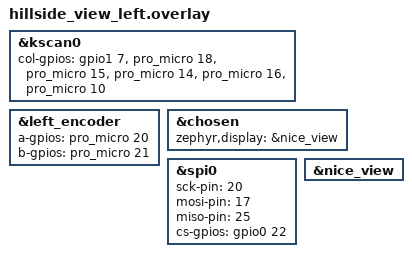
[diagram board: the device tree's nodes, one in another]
/*
 * Copyright (c) 2022 The ZMK Contributors
 *
 * SPDX-License-Identifier: MIT
 */

#include "hillside_view.dtsi"

&kscan0  {
	col-gpios
		= <&gpio1 7 GPIO_ACTIVE_HIGH>
		, <&pro_micro 18 GPIO_ACTIVE_HIGH>
		, <&pro_micro 15 GPIO_ACTIVE_HIGH>
		, <&pro_micro 14 GPIO_ACTIVE_HIGH>
		, <&pro_micro 16 GPIO_ACTIVE_HIGH>
		, <&pro_micro 10 GPIO_ACTIVE_HIGH>
		;
};

&left_encoder {
	status = "okay";
  a-gpios = <&pro_micro 20 (GPIO_ACTIVE_HIGH | GPIO_PULL_UP)>;
  b-gpios = <&pro_micro 21 (GPIO_ACTIVE_HIGH | GPIO_PULL_UP)>;
};

&chosen {
  zephyr,display = &nice_view;
};

// nice view bus
&spi0 {
  status = "okay";
  sck-pin = <20>;
  mosi-pin = <17>;
  miso-pin = <25>; // not connected port because it is not used
  cs-gpios = <&gpio0 22 GPIO_ACTIVE_HIGH>;
};

&nice_view {
  status = "okay";
};
